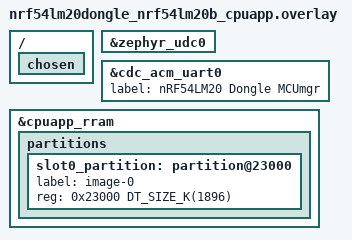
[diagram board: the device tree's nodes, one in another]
/*
 * Copyright (c) 2026 Nordic Semiconductor ASA
 *
 * SPDX-License-Identifier: LicenseRef-Nordic-5-Clause
 */

/ {
	chosen {
		/delete-property/ zephyr,console;
		/delete-property/ zephyr,shell-uart;
		/delete-property/ zephyr,bt-mon-uart;
		/delete-property/ zephyr,bt-c2h-uart;
	};
};

&zephyr_udc0 {
	/delete-node/ board_cdc_acm_uart;
	/delete-node/ mcumgr_cdc_acm_uart;
};

#include "../app.overlay"

&cdc_acm_uart0 {
	label = "nRF54LM20 Dongle MCUmgr";
};

/* This is nRF54lm20dongle_nrf54lm20b_cpuapp-specific partitioning for MCUboot and firmware loader.
 * slot0_partition defines RRAM region which can be updated by the firmware loader and booted by
 * MCUboot.
 * Beginning of the slot0_partition must match the beginning of the slot0_partition of the user
 * application, but the application can use a smaller partition and leave some space for
 * other purposes like a storage partition.
 */

/delete-node/ &storage_partition;

&cpuapp_rram {
	partitions {
		slot0_partition: partition@23000 {
			label = "image-0";
			reg = <0x23000 DT_SIZE_K(1896)>;
		};
	};
};
